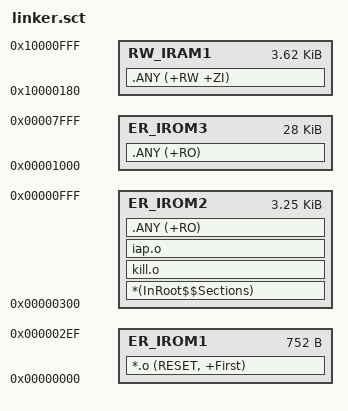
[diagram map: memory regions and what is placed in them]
; *************************************************************
; *** Scatter-Loading Description File generated by uVision ***
; *************************************************************

LR_IROM1 0x00000000 0x00000300  {    ; load region size_region
  ER_IROM1 0x00000000 0x000002F0  {  ; load address = execution address
   *.o (RESET, +First)
  }
  RW_IRAM1 0x10000180 0x00000E80  {  ; RW data
   .ANY (+RW +ZI)
  }
;  RW_IRAM2 0x10000000 0x00000050  {  ; RW data
;  }
}

LR_IROM2 0x00000300 0x00000D00  {    ; load region size_region
  ER_IROM2 0x00000300 0x00000D00  {  ; load address = execution address
   *(InRoot$$Sections)
   kill.o
   iap.o
   .ANY (+RO)
  }
}

LR_IROM3 0x00001000 0x00007000  {    ; load region size_region
  ER_IROM3 0x00001000 0x00007000  {  ; load address = execution address
   .ANY (+RO)
  }
}
